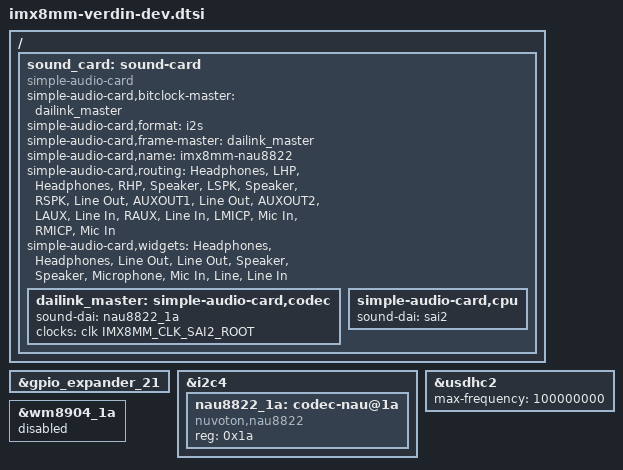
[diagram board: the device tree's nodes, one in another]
// SPDX-License-Identifier: GPL-2.0+ OR MIT
/*
 * Copyright 2020 Toradex
 */

#include "imx8mm-verdin-dahlia.dtsi"

/ {
	sound_card: sound-card {
		compatible = "simple-audio-card";
		simple-audio-card,bitclock-master = <&dailink_master>;
		simple-audio-card,format = "i2s";
		simple-audio-card,frame-master = <&dailink_master>;
		simple-audio-card,name = "imx8mm-nau8822";
		simple-audio-card,routing =
			"Headphones", "LHP",
			"Headphones", "RHP",
			"Speaker", "LSPK",
			"Speaker", "RSPK",
			"Line Out", "AUXOUT1",
			"Line Out", "AUXOUT2",
			"LAUX", "Line In",
			"RAUX", "Line In",
			"LMICP",    "Mic In",
			"RMICP",    "Mic In";
		simple-audio-card,widgets =
			"Headphones", "Headphones",
			"Line Out", "Line Out",
			"Speaker", "Speaker",
			"Microphone", "Mic In",
			"Line", "Line In";

		dailink_master: simple-audio-card,codec {
			sound-dai = <&nau8822_1a>;
			clocks = <&clk IMX8MM_CLK_SAI2_ROOT>;
		};

		simple-audio-card,cpu {
			sound-dai = <&sai2>;
		};
	};
};

&gpio_expander_21 {
	status = "okay";
};

/* Verdin I2C_1 */
&i2c4 {
	/* Audio Codec */
	nau8822_1a: codec-nau@1a {
		compatible = "nuvoton,nau8822";
		#sound-dai-cells = <0>;
		reg = <0x1a>;
	};
};

/* Limit frequency on dev board due to long traces and bad signal integrity */
&usdhc2 {
	max-frequency = <100000000>;
};

&wm8904_1a {
	status = "disabled";
};
